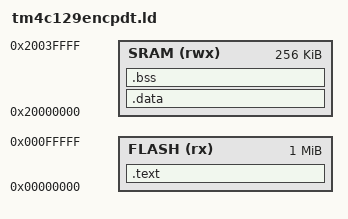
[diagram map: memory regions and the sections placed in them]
/******************************************************************************
 *
 * tm4c129encpdt.ld - Linker configuration file for TM4C129ENCPDT
 *
 * Copyright (c) 2012-2016 Texas Instruments Incorporated.  All rights reserved.
 * Software License Agreement
 *
 * Texas Instruments (TI) is supplying this software for use solely and
 * exclusively on TI's microcontroller products. The software is owned by
 * TI and/or its suppliers, and is protected under applicable copyright
 * laws. You may not combine this software with "viral" open-source
 * software in order to form a larger program.
 *
 * THIS SOFTWARE IS PROVIDED "AS IS" AND WITH ALL FAULTS.
 * NO WARRANTIES, WHETHER EXPRESS, IMPLIED OR STATUTORY, INCLUDING, BUT
 * NOT LIMITED TO, IMPLIED WARRANTIES OF MERCHANTABILITY AND FITNESS FOR
 * A PARTICULAR PURPOSE APPLY TO THIS SOFTWARE. TI SHALL NOT, UNDER ANY
 * CIRCUMSTANCES, BE LIABLE FOR SPECIAL, INCIDENTAL, OR CONSEQUENTIAL
 * DAMAGES, FOR ANY REASON WHATSOEVER.
 *
 *****************************************************************************/

MEMORY
{
    /* TM4C129ENCPDT has 1MB of FLASH and 256KB of RAM */
    FLASH (rx) : ORIGIN = 0x00000000, LENGTH = 0x00100000
    SRAM (rwx) : ORIGIN = 0x20000000, LENGTH = 0x00040000
}

SECTIONS
{
    .text :
    {
        _text = .;
        KEEP(*(.isr_vector))
        *(.text*)
        *(.rodata*)
        *(.init)
        *(.fini)
        /* Add these additional sections to fix overlap issue */
        . = ALIGN(4);
        /* Explicitly place the .ARM.exidx section to prevent overlap */
        __exidx_start = .;
        *(.ARM.exidx*)
        __exidx_end = .;
        . = ALIGN(4);
        _etext = .;
    } > FLASH

    /* Ensure .data starts at a properly aligned address after .text */
    .data : AT(ADDR(.text) + SIZEOF(.text))
    {
        . = ALIGN(4);
        _data = .;
        _ldata = LOADADDR (.data);
        *(vtable)
        *(.data*)
        . = ALIGN(4);
        _edata = .;
    } > SRAM

    .bss :
    {
        . = ALIGN(4);
        _bss = .;
        *(.bss*)
        *(COMMON)
        . = ALIGN(4);
        _ebss = .;
    } > SRAM
}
